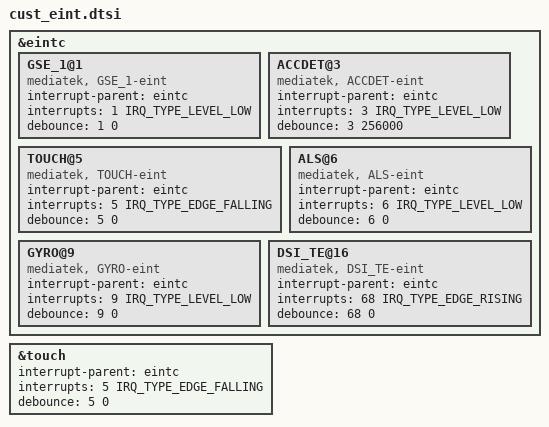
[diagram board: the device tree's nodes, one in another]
/*
 * Copyright (C) 2015 MediaTek Inc.
 *
 * This program is free software; you can redistribute it and/or modify
 * it under the terms of the GNU General Public License version 2 as
 * published by the Free Software Foundation.
 *
 * This program is distributed in the hope that it will be useful,
 * but WITHOUT ANY WARRANTY; without even the implied warranty of
 * MERCHANTABILITY or FITNESS FOR A PARTICULAR PURPOSE.
 * See http://www.gnu.org/licenses/gpl-2.0.html for more details.
 */

/*************************
 * EINT DTSI File
*************************/

#include <dt-bindings/interrupt-controller/irq.h>
#include <dt-bindings/interrupt-controller/arm-gic.h>

&eintc {

	GSE_1@1 {
		compatible = "mediatek, GSE_1-eint";
		interrupt-parent = <&eintc>;
		interrupts = <1 IRQ_TYPE_LEVEL_LOW>;
		debounce = <1 0>;
	};

	ACCDET@3 {
		compatible = "mediatek, ACCDET-eint";
		interrupt-parent = <&eintc>;
		interrupts = <3 IRQ_TYPE_LEVEL_LOW>;
		debounce = <3 256000>;
	};

	TOUCH@5 {
		compatible = "mediatek, TOUCH-eint";
		interrupt-parent = <&eintc>;
		interrupts = <5 IRQ_TYPE_EDGE_FALLING>;
		debounce = <5 0>;
	};

	ALS@6 {
		compatible = "mediatek, ALS-eint";
		interrupt-parent = <&eintc>;
		interrupts = <6 IRQ_TYPE_LEVEL_LOW>;
		debounce = <6 0>;
	};

	GYRO@9 {
		compatible = "mediatek, GYRO-eint";
		interrupt-parent = <&eintc>;
		interrupts = <9 IRQ_TYPE_LEVEL_LOW>;
		debounce = <9 0>;
	};

	DSI_TE@16 {
		compatible = "mediatek, DSI_TE-eint";
		interrupt-parent = <&eintc>;
		interrupts = <68 IRQ_TYPE_EDGE_RISING>;
		debounce = <68 0>;
	};

};
&touch {
	interrupt-parent = <&eintc>;
	interrupts = <5 IRQ_TYPE_EDGE_FALLING>;
	debounce = <5 0>;
};
